# STM32U5G9xx register map
File version: 1.0
Registers are 32-bit, read-write, reset 0x0 unless marked. A register's access mark holds for its fields unless they carry their own. Offsets are from the block's base; [hi:lo] are bit positions; {n}, {i} and the like mark numbered series; 'fields as' and 'values as' point back to an identical list.

## GTZC_TZIC1
Base 0x40032800
Same registers: GTZC_TZIC1_S 0x50032800
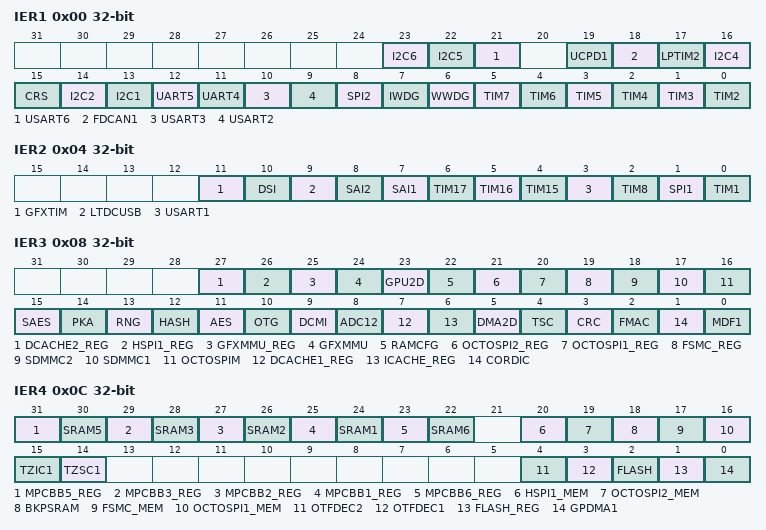
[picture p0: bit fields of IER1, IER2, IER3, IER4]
0x00 IER1 — TZIC interrupt enable register 1
  [23] I2C6, [22] I2C5, [21] USART6, [19] UCPD1, [18] FDCAN1, [17] LPTIM2, [16] I2C4, [15] CRS, [14] I2C2, [13] I2C1, [12] UART5, [11] UART4, [10] USART3, [9] USART2, [8] SPI2, [7] IWDG, [6] WWDG, [n-2] TIM{n} (n=2..7)
0x04 IER2 — TZIC interrupt enable register 2
  [11] GFXTIM, [10] DSI, [9] LTDCUSB, [8] SAI2, [7] SAI1, [6] TIM17, [5] TIM16, [4] TIM15, [3] USART1, [2] TIM8, [1] SPI1, [0] TIM1
0x08 IER3 — TZIC interrupt enable register 3
  [27] DCACHE2_REG, [26] HSPI1_REG, [25] GFXMMU_REG, [24] GFXMMU, [23] GPU2D, [22] RAMCFG, [21] OCTOSPI2_REG, [20] OCTOSPI1_REG, [19] FSMC_REG, [18] SDMMC2, [17] SDMMC1, [16] OCTOSPIM, [15] SAES, [14] PKA, [13] RNG, [12] HASH, [11] AES, [10] OTG, [9] DCMI, [8] ADC12, [7] DCACHE1_REG, [6] ICACHE_REG, [5] DMA2D, [4] TSC, [3] CRC, [2] FMAC, [1] CORDIC, [0] MDF1
0x0C IER4 — TZIC interrupt enable register 4
  [31] MPCBB5_REG, [30] SRAM5, [29] MPCBB3_REG, [28] SRAM3, [27] MPCBB2_REG, [26] SRAM2, [25] MPCBB1_REG, [24] SRAM1, [23] MPCBB6_REG, [22] SRAM6, [20] HSPI1_MEM, [19] OCTOSPI2_MEM, [18] BKPSRAM, [17] FSMC_MEM, [16] OCTOSPI1_MEM, [15] TZIC1, [14] TZSC1, [4] OTFDEC2, [3] OTFDEC1, [2] FLASH, [1] FLASH_REG, [0] GPDMA1
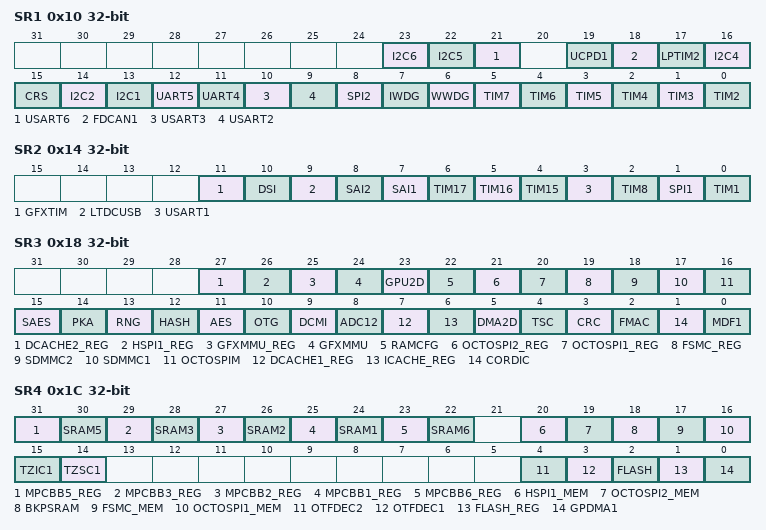
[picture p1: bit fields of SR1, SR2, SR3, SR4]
0x10 SR1 — TZIC status register 1
  fields as IER1
0x14 SR2 — TZIC status register 2
  fields as IER2
0x18 SR3 — TZIC status register 3
  fields as IER3
0x1C SR4 — TZIC status register 4
  fields as IER4
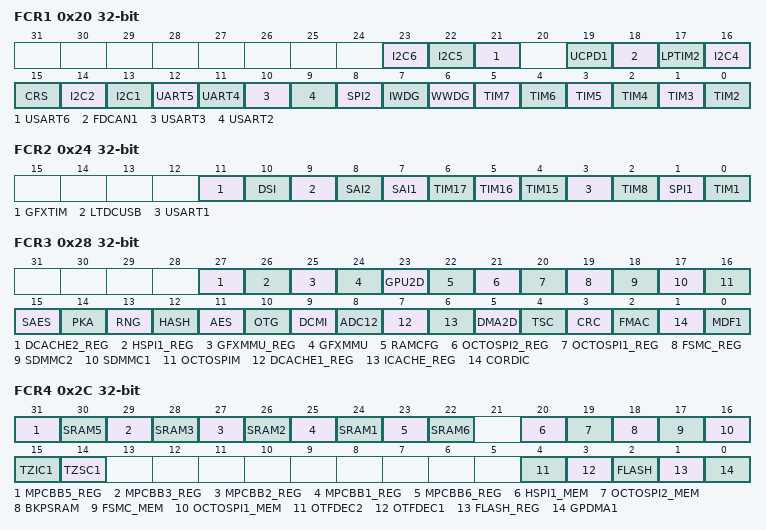
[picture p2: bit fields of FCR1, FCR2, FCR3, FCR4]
0x20 FCR1 — TZIC flag clear register 1
  fields as IER1
0x24 FCR2 — TZIC flag clear register 2
  fields as IER2
0x28 FCR3 — TZIC flag clear register 3
  fields as IER3
0x2C FCR4 — TZIC flag clear register 3
  fields as IER4

## GTZC_MPCBB1
Base 0x40032C00
Same registers: GTZC_MPCBB2 0x40033000, GTZC_MPCBB3 0x40033400, GTZC_MPCBB5 0x40033800, GTZC_MPCBB6 0x40033C00, GTZC_MPCBB4 0x46023800, GTZC_MPCBB1_S 0x50032C00, GTZC_MPCBB2_S 0x50033000, GTZC_MPCBB3_S 0x50033400, GTZC_MPCBB5_S 0x50033800, GTZC_MPCBB6_S 0x50033C00, GTZC_MPCBB4_S 0x56023800
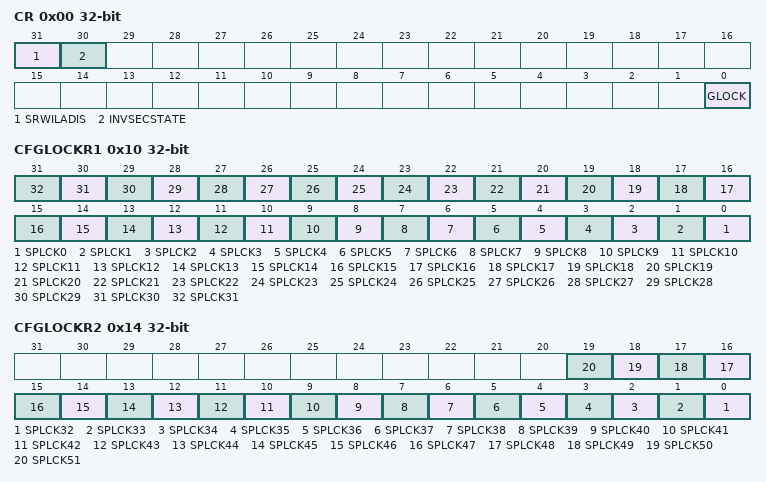
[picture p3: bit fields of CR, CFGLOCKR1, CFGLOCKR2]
0x00 CR — MPCBBx control register
  [31] SRWILADIS, [30] INVSECSTATE, [0] GLOCK
0x10 CFGLOCKR1 — MPCBBx Configuration lock register 1
  [n] SPLCK{n} (n=0..31)
0x14 CFGLOCKR2 — MPCBBx Configuration lock register 2
  [n-32] SPLCK{n} (n=32..51)
{0x100+4i} SECCFGR{i} (i=0..51) — MPCBBx security configuration registers
{0x200+4i} PRIVCFGR{i} (i=0..51) — MPCBBx privilege configuration registers

## GPIOA — General Purpose I/O
Base 0x42020000
Same registers: GPIOB 0x42020400, GPIOC 0x42020800, GPIOD 0x42020C00, GPIOE 0x42021000, GPIOF 0x42021400, GPIOG 0x42021800, GPIOH 0x42021C00, GPIOI 0x42022000, GPIOJ 0x42022400, GPIOA_S 0x52020000, GPIOB_S 0x52020400, GPIOC_S 0x52020800, GPIOD_S 0x52020C00, GPIOE_S 0x52021000, GPIOF_S 0x52021400, GPIOG_S 0x52021800, GPIOH_S 0x52021C00, GPIOI_S 0x52022000, GPIOJ_S 0x52022400
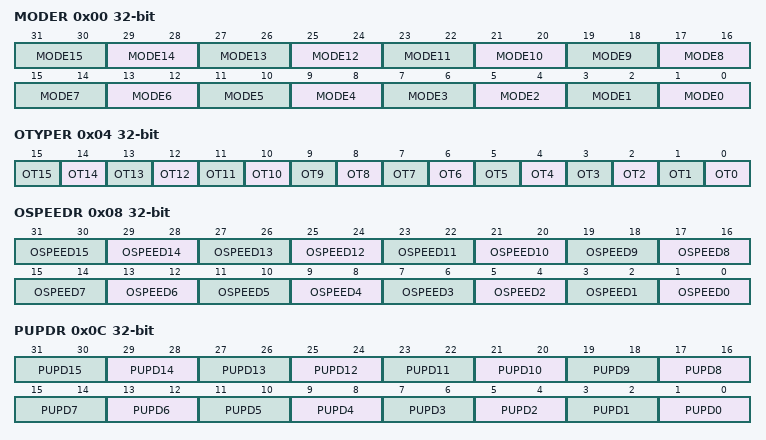
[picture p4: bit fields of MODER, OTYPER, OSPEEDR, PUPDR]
0x00 MODER — GPIO port mode register
  [2n+1:2n] MODE{n} (n=0..15)
0x04 OTYPER — GPIO port output type register
  [n] OT{n} (n=0..15)
0x08 OSPEEDR — GPIO port output speed register
  [2n+1:2n] OSPEED{n} (n=0..15)
0x0C PUPDR — GPIO port pull-up/pull-down register
  [2n+1:2n] PUPD{n} (n=0..15)
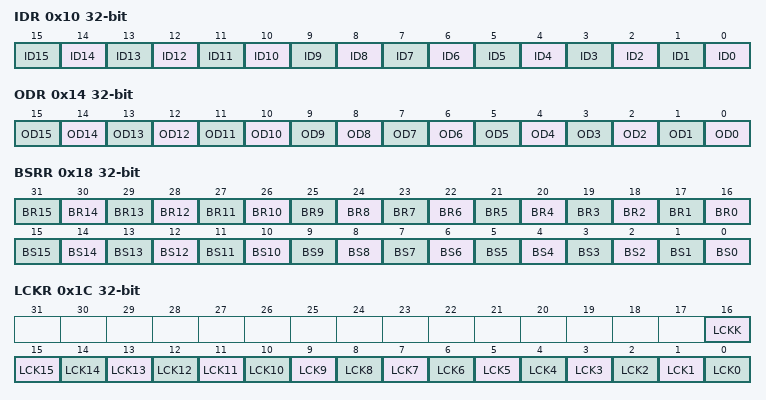
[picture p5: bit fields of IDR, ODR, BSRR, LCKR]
0x10 IDR — GPIO port input data register
  [n] ID{n} (n=0..15)
0x14 ODR — GPIO port output data register
  [n] OD{n} (n=0..15)
0x18 BSRR — GPIO port bit set/reset register
  [n+16] BR{n} (n=0..15), [n] BS{n} (n=0..15)
0x1C LCKR — GPIO port configuration lock register
  [16] LCKK, [n] LCK{n} (n=0..15)
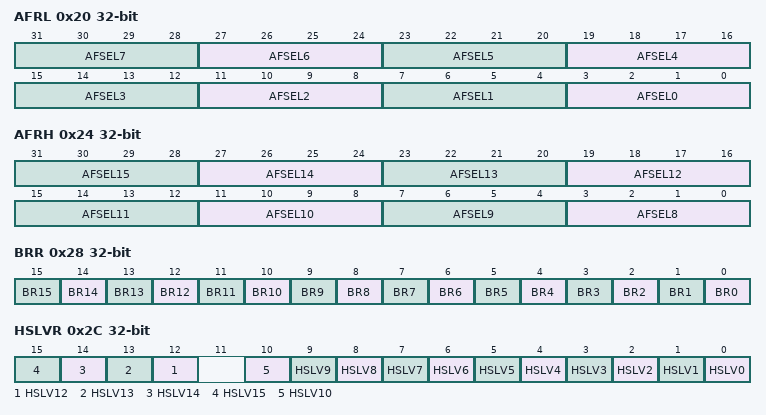
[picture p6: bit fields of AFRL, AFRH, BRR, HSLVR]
0x20 AFRL — GPIO alternate function registers
  [4n+3:4n] AFSEL{n} (n=0..7)
0x24 AFRH — GPIO alternate function registers
  [4n-29:4n-32] AFSEL{n} (n=8..15)
0x28 BRR — GPIO Bit Reset register
  [n] BR{n} (n=0..15)
0x2C HSLVR — GPIO high-speed low voltage register
  [n] HSLV{n} (n=12..15), [n] HSLV{n} (n=0..10)
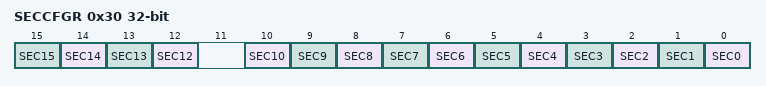
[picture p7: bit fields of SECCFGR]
0x30 SECCFGR — GPIO secure configuration register
  [n] SEC{n} (n=12..15), [n] SEC{n} (n=0..10)

## LPGPIO1 — General Purpose I/O
Base 0x46020000
Same registers: LPGPIO1_S 0x56020000
Registers as GPIOA; these are added or differ:
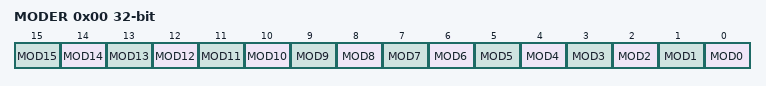
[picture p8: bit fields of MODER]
0x00 MODER — GPIO port mode register
  [n] MOD{n} (n=0..15)
